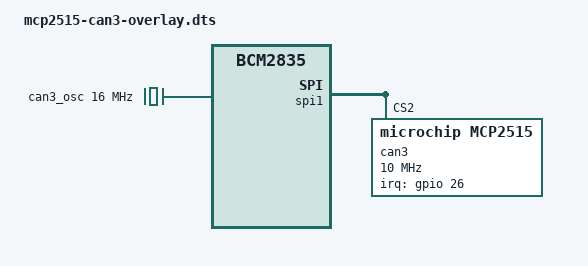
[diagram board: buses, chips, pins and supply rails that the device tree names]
/dts-v1/;
/plugin/;

 / {
     compatible = "brcm,bcm2835";

     fragment@0 {
         target = <&spi1>;
         __overlay__ {
             status = "okay";
         };
     };

     fragment@1 {
         target = <&spidev0>;
         __overlay__ {
             status = "disabled";
         };
     };

     fragment@2 {
         target = <&gpio>;
         __overlay__ {
             can3_pins: can3_pins {
                 brcm,pins = <26>;             // GPIO26 = INT
                 brcm,function = <0>;          // Input
             };
         };
     };

     fragment@3 {
         target-path = "/";
         __overlay__ {
             can3_osc: can3_osc {
                 compatible = "fixed-clock";
                 #clock-cells = <0>;
                 clock-frequency = <16000000>;
             };
         };
     };

     fragment@4 {
         target = <&spi1>;
         __overlay__ {
             #address-cells = <1>;
             #size-cells = <0>;
             can3: mcp2515@2 {
                 reg = <2>; // CS2 = GPIO18 = spi1.2
                 compatible = "microchip,mcp2515";
                 pinctrl-names = "default";
                 pinctrl-0 = <&can3_pins>;
                 spi-max-frequency = <10000000>;
                 interrupt-parent = <&gpio>;
                 interrupts = <26 0>;
                 clocks = <&can3_osc>;
             };
         };
     };

     __overrides__ {
         oscillator = <&can3_osc>,"clock-frequency:0";
         spimaxfrequency = <&can3>,"spi-max-frequency:0";
         interrupt = <&can3_pins>,"brcm,pins:0",<&can3>,"interrupts:0";
     };
 };
